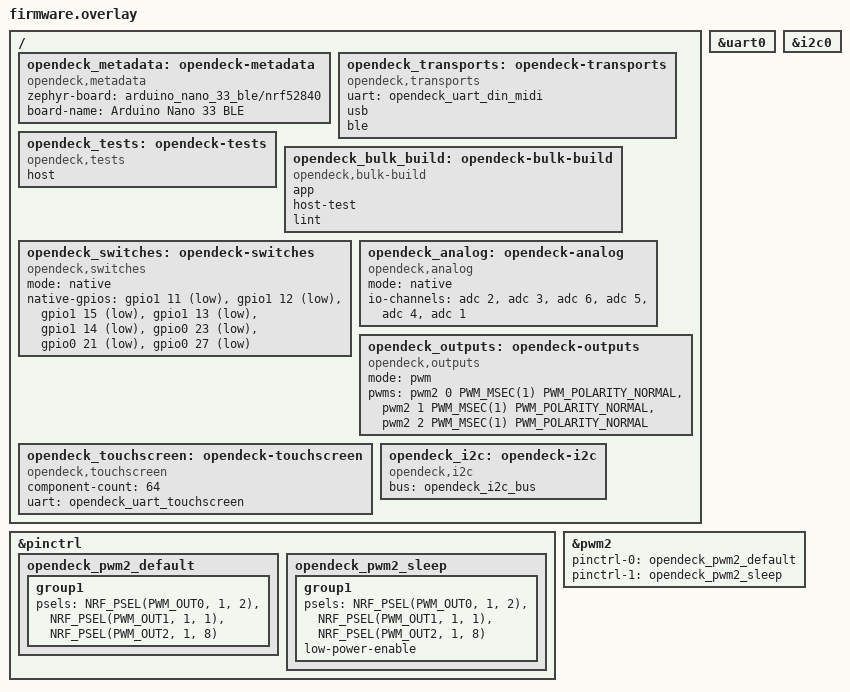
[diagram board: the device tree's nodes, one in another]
/ {
    opendeck_metadata: opendeck-metadata {
        compatible = "opendeck,metadata";
        zephyr-board = "arduino_nano_33_ble/nrf52840";
        board-name = "Arduino Nano 33 BLE";
    };

    opendeck_transports: opendeck-transports {
        compatible = "opendeck,transports";
        uart = <&opendeck_uart_din_midi>;
        usb;
        ble;
    };

    opendeck_tests: opendeck-tests {
        compatible = "opendeck,tests";
        host;
    };

    opendeck_bulk_build: opendeck-bulk-build {
        compatible = "opendeck,bulk-build";
        app;
        host-test;
        lint;
    };

    opendeck_switches: opendeck-switches {
        compatible = "opendeck,switches";
        mode = "native";
        native-gpios =
            <&gpio1 11 (GPIO_PULL_UP | GPIO_ACTIVE_LOW)>, /* D2 */
            <&gpio1 12 (GPIO_PULL_UP | GPIO_ACTIVE_LOW)>, /* D3 */
            <&gpio1 15 (GPIO_PULL_UP | GPIO_ACTIVE_LOW)>, /* D4 */
            <&gpio1 13 (GPIO_PULL_UP | GPIO_ACTIVE_LOW)>, /* D5 */
            <&gpio1 14 (GPIO_PULL_UP | GPIO_ACTIVE_LOW)>, /* D6 */
            <&gpio0 23 (GPIO_PULL_UP | GPIO_ACTIVE_LOW)>, /* D7 */
            <&gpio0 21 (GPIO_PULL_UP | GPIO_ACTIVE_LOW)>, /* D8 */
            <&gpio0 27 (GPIO_PULL_UP | GPIO_ACTIVE_LOW)>; /* D9 */
    };

    opendeck_analog: opendeck-analog {
        compatible = "opendeck,analog";
        mode = "native";
        io-channels =
            <&adc 2>, /* A0 */
            <&adc 3>, /* A1 */
            <&adc 6>, /* A2 */
            <&adc 5>, /* A3 */
            <&adc 4>, /* A6 */
            <&adc 1>; /* A7 */
    };

    opendeck_outputs: opendeck-outputs {
        compatible = "opendeck,outputs";
        mode = "pwm";
        pwms =
            <&pwm2 0 PWM_MSEC(1) PWM_POLARITY_NORMAL>, /* D10 */
            <&pwm2 1 PWM_MSEC(1) PWM_POLARITY_NORMAL>, /* D11 */
            <&pwm2 2 PWM_MSEC(1) PWM_POLARITY_NORMAL>; /* D12 */
    };

    opendeck_touchscreen: opendeck-touchscreen {
        compatible = "opendeck,touchscreen";
        component-count = <64>;
        uart = <&opendeck_uart_touchscreen>;
    };
    opendeck_i2c: opendeck-i2c {
        compatible = "opendeck,i2c";
        bus = <&opendeck_i2c_bus>;
    };
};

&uart0 {
    status = "okay";
};

&i2c0 {
    status = "okay";
};

&pinctrl {
    opendeck_pwm2_default: opendeck_pwm2_default {
        group1 {
            psels = <NRF_PSEL(PWM_OUT0, 1, 2)>,
                    <NRF_PSEL(PWM_OUT1, 1, 1)>,
                    <NRF_PSEL(PWM_OUT2, 1, 8)>;
        };
    };

    opendeck_pwm2_sleep: opendeck_pwm2_sleep {
        group1 {
            psels = <NRF_PSEL(PWM_OUT0, 1, 2)>,
                    <NRF_PSEL(PWM_OUT1, 1, 1)>,
                    <NRF_PSEL(PWM_OUT2, 1, 8)>;
            low-power-enable;
        };
    };
};

&pwm2 {
    pinctrl-0 = <&opendeck_pwm2_default>;
    pinctrl-1 = <&opendeck_pwm2_sleep>;
    pinctrl-names = "default", "sleep";
    status = "okay";
};
